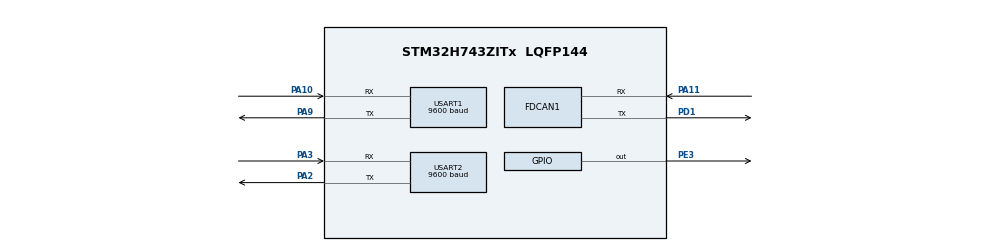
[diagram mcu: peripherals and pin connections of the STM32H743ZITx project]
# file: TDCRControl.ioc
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CORTEX_M7.default_mode_Activation=1
FDCAN1.CalculateBaudRateNominal=100000
FDCAN1.CalculateTimeBitNominal=10000
FDCAN1.CalculateTimeQuantumNominal=250.0
FDCAN1.ExtFiltersNbr=2
FDCAN1.NominalPrescaler=20
FDCAN1.NominalSyncJumpWidth=4
FDCAN1.NominalTimeSeg1=31
FDCAN1.NominalTimeSeg2=8
FDCAN1.RxFifo0ElmtsNbr=32
FDCAN1.RxFifo1ElmtsNbr=0
FDCAN1.StdFiltersNbr=1
FDCAN1.TxFifoQueueElmtsNbr=32
FREERTOS.Queues01=CmdQueue,16,uint8_t,0,Dynamic,NULL,NULL;SensorDataQueue,16,uint8_t,0,Dynamic,NULL,NULL
FREERTOS.Tasks01=defaultTask,24,128,StartDefaultTask,Default,NULL,Dynamic,NULL,NULL;CmdCtrlTask,8,512,StartCmdCtrlTask,As external,NULL,Dynamic,NULL,NULL;SensorDataTask,8,512,StartSensorDataTask,As external,NULL,Dynamic,NULL,NULL;DataParserTask,8,512,StartDataParserTask,As external,NULL,Dynamic,NULL,NULL
Mcu.Family=STM32H7
Mcu.Name=STM32H743ZITx
Mcu.Package=LQFP144
NVIC.FDCAN1_IT0_IRQn=true\:5\:0\:false\:false\:true\:true\:true\:true\:true
NVIC.PriorityGroup=NVIC_PRIORITYGROUP_4
NVIC.RCC_IRQn=true\:5\:0\:false\:false\:true\:true\:true\:false\:true
NVIC.TIM4_IRQn=true\:15\:0\:false\:false\:true\:false\:false\:true\:true
NVIC.TimeBase=TIM4_IRQn
NVIC.TimeBaseIP=TIM4
NVIC.USART1_IRQn=true\:5\:0\:false\:false\:true\:true\:true\:true\:true
NVIC.USART2_IRQn=true\:5\:0\:false\:false\:true\:true\:true\:true\:true
PA10.Mode=Asynchronous
PA10.Signal=USART1_RX
PA11.Mode=FDCAN_Activate
PA11.Signal=FDCAN1_RX
PA2.Mode=Asynchronous
PA2.Signal=USART2_TX
PA3.Mode=Asynchronous
PA3.Signal=USART2_RX
PA9.Mode=Asynchronous
PA9.Signal=USART1_TX
PD1.Mode=FDCAN_Activate
PD1.Signal=FDCAN1_TX
PE3.GPIO_PuPd=GPIO_NOPULL
PE3.Signal=GPIO_Output
PH0-OSC_IN\ (PH0).Mode=HSE-External-Oscillator
PH0-OSC_IN\ (PH0).Signal=RCC_OSC_IN
PH1-OSC_OUT\ (PH1).Mode=HSE-External-Oscillator
PH1-OSC_OUT\ (PH1).Signal=RCC_OSC_OUT
ProjectManager.HeapSize=0x200
ProjectManager.StackSize=0x400
ProjectManager.TargetToolchain=CMake
RCC.ADCFreq_Value=468750000
RCC.APB1Freq_Value=120000000
RCC.APB2Freq_Value=120000000
RCC.APB3Freq_Value=120000000
RCC.APB4Freq_Value=120000000
RCC.CortexFreq_Value=480000000
RCC.D1PPRE=RCC_APB3_DIV2
RCC.D2PPRE1=RCC_APB1_DIV2
RCC.D2PPRE2=RCC_APB2_DIV2
RCC.D3PPRE=RCC_APB4_DIV2
RCC.DIVM1=5
RCC.DIVM2=4
RCC.DIVN1=192
RCC.DIVN2=150
RCC.DIVQ1=12
RCC.DIVQ2=12
RCC.FDCANCLockSelection=RCC_FDCANCLKSOURCE_PLL
RCC.HCLKFreq_Value=240000000
RCC.HPRE=RCC_HCLK_DIV2
RCC.PLL2FRACN=0
RCC.PLL3FRACN=0
RCC.PLLFRACN=0
RCC.PLLSourceVirtual=RCC_PLLSOURCE_HSE
RCC.SYSCLKFreq_VALUE=480000000
RCC.SYSCLKSource=RCC_SYSCLKSOURCE_PLLCLK
RCC.USBFreq_Value=80000000
USART1.BaudRate=9600
USART1.VirtualMode-Asynchronous=VM_ASYNC
USART2.BaudRate=9600
USART2.VirtualMode-Asynchronous=VM_ASYNC
VP_FREERTOS_VS_CMSIS_V2.Mode=CMSIS_V2
VP_MEMORYMAP_VS_MEMORYMAP.Mode=CurAppReg
VP_SYS_VS_tim4.Mode=TIM4
board=custom

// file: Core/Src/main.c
/* USER CODE BEGIN Header */
/**
  ******************************************************************************
  * @file           : main.c
  * @brief          : Main program body
  ******************************************************************************
  * @attention
  *
  * Copyright (c) 2026 STMicroelectronics.
  * All rights reserved.
  *
  * This software is licensed under terms that can be found in the LICENSE file
  * in the root directory of this software component.
  * If no LICENSE file comes with this software, it is provided AS-IS.
  *
  ******************************************************************************
  */
/* USER CODE END Header */
#include "main.h"
#include "cmsis_os.h"
#include "fdcan.h"
#include "usart.h"
#include "gpio.h"

/* USER CODE BEGIN Includes */
#include "CR/CR.h"
#include "Communicate/can_driver.h"
/* USER CODE END Includes */

void SystemClock_Config(void);
static void MPU_Config(void);
void MX_FREERTOS_Init(void);

int main(void)
{

  /* MPU Configuration--------------------------------------------------------*/
  MPU_Config();

  /* MCU Configuration--------------------------------------------------------*/

  /* Reset of all peripherals, Initializes the Flash interface and the Systick. */
  HAL_Init();

  /* Configure the system clock */
  SystemClock_Config();

  /* Initialize all configured peripherals */
  MX_GPIO_Init();
  MX_FDCAN1_Init();
  MX_USART1_UART_Init();
  MX_USART2_UART_Init();
  /* USER CODE BEGIN 2 */
  /* ---- 应用层模块初始化（外设已就绪，不依赖 RTOS 对象）---- */
  CR_init();   /* 电机参数 / SDM / CMCU-06 压力传感器 (USART2, 115200bps) */
  /* USER CODE END 2 */

  /* Init scheduler */
  osKernelInitialize();  /* Call init function for freertos objects (in cmsis_os2.c) */
  MX_FREERTOS_Init();

  /* Start scheduler */
  osKernelStart();

  /* We should never get here as control is now taken by the scheduler */

  /* Infinite loop */
  while (1)
  {

  }
}

void SystemClock_Config(void)
{
  RCC_OscInitTypeDef RCC_OscInitStruct = {0};
  RCC_ClkInitTypeDef RCC_ClkInitStruct = {0};

  /** Supply configuration update enable
  */
  HAL_PWREx_ConfigSupply(PWR_LDO_SUPPLY);

  /** Configure the main internal regulator output voltage
  */
  __HAL_PWR_VOLTAGESCALING_CONFIG(PWR_REGULATOR_VOLTAGE_SCALE0);

  while(!__HAL_PWR_GET_FLAG(PWR_FLAG_VOSRDY)) {}

  /** Initializes the RCC Oscillators according to the specified parameters
  * in the RCC_OscInitTypeDef structure.
  */
  RCC_OscInitStruct.OscillatorType = RCC_OSCILLATORTYPE_HSE;
  RCC_OscInitStruct.HSEState = RCC_HSE_ON;
  RCC_OscInitStruct.PLL.PLLState = RCC_PLL_ON;
  RCC_OscInitStruct.PLL.PLLSource = RCC_PLLSOURCE_HSE;
  RCC_OscInitStruct.PLL.PLLM = 5;
  RCC_OscInitStruct.PLL.PLLN = 192;
  RCC_OscInitStruct.PLL.PLLP = 2;
  RCC_OscInitStruct.PLL.PLLQ = 12;
  RCC_OscInitStruct.PLL.PLLR = 2;
  RCC_OscInitStruct.PLL.PLLRGE = RCC_PLL1VCIRANGE_2;
  RCC_OscInitStruct.PLL.PLLVCOSEL = RCC_PLL1VCOWIDE;
  RCC_OscInitStruct.PLL.PLLFRACN = 0;
  if (HAL_RCC_OscConfig(&RCC_OscInitStruct) != HAL_OK)
  {
    Error_Handler();
  }

  /** Initializes the CPU, AHB and APB buses clocks
  */
  RCC_ClkInitStruct.ClockType = RCC_CLOCKTYPE_HCLK|RCC_CLOCKTYPE_SYSCLK
                              |RCC_CLOCKTYPE_PCLK1|RCC_CLOCKTYPE_PCLK2
                              |RCC_CLOCKTYPE_D3PCLK1|RCC_CLOCKTYPE_D1PCLK1;
  RCC_ClkInitStruct.SYSCLKSource = RCC_SYSCLKSOURCE_PLLCLK;
  RCC_ClkInitStruct.SYSCLKDivider = RCC_SYSCLK_DIV1;
  RCC_ClkInitStruct.AHBCLKDivider = RCC_HCLK_DIV2;
  RCC_ClkInitStruct.APB3CLKDivider = RCC_APB3_DIV2;
  RCC_ClkInitStruct.APB1CLKDivider = RCC_APB1_DIV2;
  RCC_ClkInitStruct.APB2CLKDivider = RCC_APB2_DIV2;
  RCC_ClkInitStruct.APB4CLKDivider = RCC_APB4_DIV2;

  if (HAL_RCC_ClockConfig(&RCC_ClkInitStruct, FLASH_LATENCY_4) != HAL_OK)
  {
    Error_Handler();
  }
}

 /* MPU Configuration */

void MPU_Config(void)
{
  MPU_Region_InitTypeDef MPU_InitStruct = {0};

  /* Disables the MPU */
  HAL_MPU_Disable();

  /** Initializes and configures the Region and the memory to be protected
  */
  MPU_InitStruct.Enable = MPU_REGION_ENABLE;
  MPU_InitStruct.Number = MPU_REGION_NUMBER0;
  MPU_InitStruct.BaseAddress = 0x0;
  MPU_InitStruct.Size = MPU_REGION_SIZE_4GB;
  MPU_InitStruct.SubRegionDisable = 0x87;
  MPU_InitStruct.TypeExtField = MPU_TEX_LEVEL0;
  MPU_InitStruct.AccessPermission = MPU_REGION_NO_ACCESS;
  MPU_InitStruct.DisableExec = MPU_INSTRUCTION_ACCESS_DISABLE;
  MPU_InitStruct.IsShareable = MPU_ACCESS_SHAREABLE;
  MPU_InitStruct.IsCacheable = MPU_ACCESS_NOT_CACHEABLE;
  MPU_InitStruct.IsBufferable = MPU_ACCESS_NOT_BUFFERABLE;

  HAL_MPU_ConfigRegion(&MPU_InitStruct);
  /* Enables the MPU */
  HAL_MPU_Enable(MPU_PRIVILEGED_DEFAULT);

}

void HAL_TIM_PeriodElapsedCallback(TIM_HandleTypeDef *htim)
{
  if (htim->Instance == TIM4)
  {
    HAL_IncTick();
  }
}

void Error_Handler(void)
{
  __disable_irq();
  while (1)
  {
  }
}

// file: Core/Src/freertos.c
/* USER CODE BEGIN Header */
/**
  ******************************************************************************
  * File Name          : freertos.c
  * Description        : Code for freertos applications
  ******************************************************************************
  * @attention
  *
  * Copyright (c) 2026 STMicroelectronics.
  * All rights reserved.
  *
  * This software is licensed under terms that can be found in the LICENSE file
  * in the root directory of this software component.
  * If no LICENSE file comes with this software, it is provided AS-IS.
  *
  ******************************************************************************
  */
/* USER CODE END Header */

#include "FreeRTOS.h"
#include "task.h"
#include "main.h"
#include "cmsis_os.h"

/* USER CODE BEGIN Includes */
#include "usart.h"
#include "Communicate/can_driver.h"
/* USER CODE END Includes */

/* Definitions for defaultTask */
osThreadId_t defaultTaskHandle;
const osThreadAttr_t defaultTask_attributes = {
  .name = "defaultTask",
  .stack_size = 128 * 4,
  .priority = (osPriority_t) osPriorityNormal,
};
/* Definitions for CmdCtrlTask */
osThreadId_t CmdCtrlTaskHandle;
const osThreadAttr_t CmdCtrlTask_attributes = {
  .name = "CmdCtrlTask",
  .stack_size = 512 * 4,
  .priority = (osPriority_t) osPriorityLow,
};
/* Definitions for SensorDataTask */
osThreadId_t SensorDataTaskHandle;
const osThreadAttr_t SensorDataTask_attributes = {
  .name = "SensorDataTask",
  .stack_size = 512 * 4,
  .priority = (osPriority_t) osPriorityLow,
};
/* Definitions for DataParserTask */
osThreadId_t DataParserTaskHandle;
const osThreadAttr_t DataParserTask_attributes = {
  .name = "DataParserTask",
  .stack_size = 512 * 4,
  .priority = (osPriority_t) osPriorityLow,
};
/* Definitions for CmdQueue */
osMessageQueueId_t CmdQueueHandle;
const osMessageQueueAttr_t CmdQueue_attributes = {
  .name = "CmdQueue"
};
/* Definitions for SensorDataQueue */
osMessageQueueId_t SensorDataQueueHandle;
const osMessageQueueAttr_t SensorDataQueue_attributes = {
  .name = "SensorDataQueue"
};

void StartDefaultTask(void *argument);
extern void StartCmdCtrlTask(void *argument);
extern void StartSensorDataTask(void *argument);
extern void StartDataParserTask(void *argument);

void MX_FREERTOS_Init(void); /* (MISRA C 2004 rule 8.1) */

void MX_FREERTOS_Init(void) {

  /* Create the queue(s) */
  /* creation of CmdQueue */
  CmdQueueHandle = osMessageQueueNew (16, sizeof(uint8_t), &CmdQueue_attributes);

  /* creation of SensorDataQueue */
  SensorDataQueueHandle = osMessageQueueNew (16, sizeof(uint8_t), &SensorDataQueue_attributes);

  /* Create the thread(s) */
  /* creation of defaultTask */
  defaultTaskHandle = osThreadNew(StartDefaultTask, NULL, &defaultTask_attributes);

  /* creation of CmdCtrlTask */
  CmdCtrlTaskHandle = osThreadNew(StartCmdCtrlTask, NULL, &CmdCtrlTask_attributes);

  /* creation of SensorDataTask */
  SensorDataTaskHandle = osThreadNew(StartSensorDataTask, NULL, &SensorDataTask_attributes);

  /* creation of DataParserTask */
  DataParserTaskHandle = osThreadNew(StartDataParserTask, NULL, &DataParserTask_attributes);

}

void StartDefaultTask(void *argument)
{
  /* USER CODE BEGIN StartDefaultTask */
  /* CAN 驱动初始化: 创建接收队列 + 过滤器 + HAL_FDCAN_Start + 中断通知。
   * 放在调度器启动之后、本任务优先级(Normal)高于其它任务(Low)，
   * 保证 CmdCtrlTask / SensorDataTask 首次用 CAN 之前已就绪；
   * 同时避开"调度器启动前调用 osMessageQueueNew 导致 BASEPRI 被永久抬高"的坑。 */
  CAN_Driver_Init();

  /* 启动 USART1/USART2 单字节中断接收 */
  UART_Receive_Init();

  /* Infinite loop */
  for(;;)
  {
    osDelay(1);
  }
  /* USER CODE END StartDefaultTask */
}
